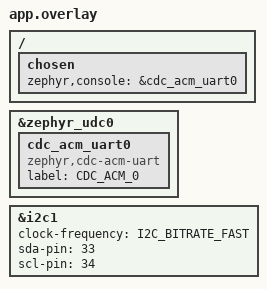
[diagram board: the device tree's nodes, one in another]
/ {
        chosen {
                zephyr,console = &cdc_acm_uart0;
        };
};

&zephyr_udc0 {
        cdc_acm_uart0: cdc_acm_uart0 {
                compatible = "zephyr,cdc-acm-uart";
                label = "CDC_ACM_0";
        };
};

/* Add I2C1 support on Particle Mesh via nRF52840 TWI1
 *
 * NOTE: This file is replicated in particle_{argon,xenon}.
 * Changes should be made in all instances. */
&i2c1 { /* feather I2C1 */
	status = "okay";
        clock-frequency = <I2C_BITRATE_FAST>;
	sda-pin = <33>;
	scl-pin = <34>;
};
